AUTOSAR XML (schema 4-2-2)
package /ETAS_BIP
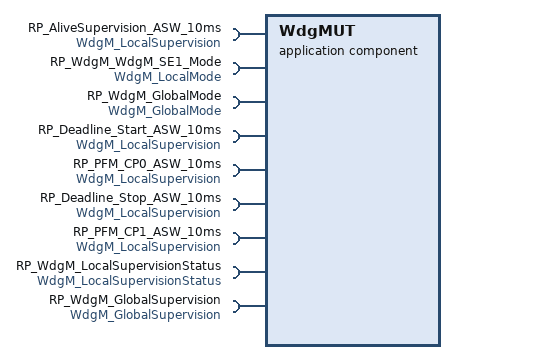
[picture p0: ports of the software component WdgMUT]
  application sw component type WdgMUT
    9 x require port:
      RP_AliveSupervision_ASW_10ms: required-interface=WdgM_LocalSupervision
      RP_WdgM_WdgM_SE1_Mode: required-interface=WdgM_LocalMode
      RP_WdgM_GlobalMode: required-interface=WdgM_GlobalMode
      RP_Deadline_Start_ASW_10ms: required-interface=WdgM_LocalSupervision
      RP_PFM_CP0_ASW_10ms: required-interface=WdgM_LocalSupervision
      RP_Deadline_Stop_ASW_10ms: required-interface=WdgM_LocalSupervision
      RP_PFM_CP1_ASW_10ms: required-interface=WdgM_LocalSupervision
      RP_WdgM_LocalSupervisionStatus: required-interface=WdgM_LocalSupervisionStatus
      RP_WdgM_GlobalSupervision: required-interface=WdgM_GlobalSupervision
    behavior IB_WdgMUT: data-type-mapping=WdgM_Type_Map
      5 x timing event, all with period=0.01:
        TE_ASW_10ms_Alive: start-on-event=RE_WdgMUT_ASW_10ms_Alive
        TE_WdgM_LocalSupervisionStatus: start-on-event=RE_WdgM_LocalSupervisionStatus
        TE_WdgM_GlobalSupervision: start-on-event=RE_WdgM_GlobalSupervision
        TE_ASW_10ms_Deadline: start-on-event=RE_WdgMUT_ASW_10ms_Deadline
        TE_ASW_10ms_Logical: start-on-event=RE_WdgMUT_ASW_10ms_Logical
      5 x runnable:
        RE_WdgMUT_ASW_10ms_Alive: mode-access-points=[RP_WdgM_WdgM_SE1_Mode.currentMode, RP_WdgM_GlobalMode.currentMode]
          sync call SSCP_Alive_CP: operation=RP_AliveSupervision_ASW_10ms.CheckpointReached
        RE_WdgMUT_ASW_10ms_Deadline
          sync call SSCP_Deadline_Start_CP: operation=RP_Deadline_Start_ASW_10ms.CheckpointReached
          sync call SSCP_Deadline_Stop_CP: operation=RP_Deadline_Stop_ASW_10ms.CheckpointReached
        RE_WdgMUT_ASW_10ms_Logical
          sync call SSCP_PFM_CP_0: operation=RP_PFM_CP0_ASW_10ms.CheckpointReached
          sync call SSCP_PFM_CP_1: operation=RP_PFM_CP1_ASW_10ms.CheckpointReached
        RE_WdgM_LocalSupervisionStatus
          sync call SynchronousServerCallPoint_0: operation=RP_WdgM_LocalSupervisionStatus.GetLocalStatus
        RE_WdgM_GlobalSupervision
          5 x sync call:
            SynchronousServerCallPoint_0: operation=RP_WdgM_GlobalSupervision.GetFirstExpiredSEID
            SynchronousServerCallPoint_1: operation=RP_WdgM_GlobalSupervision.GetGlobalStatus
            SynchronousServerCallPoint_2: operation=RP_WdgM_GlobalSupervision.GetMode
            SynchronousServerCallPoint_3: operation=RP_WdgM_GlobalSupervision.PerformReset
            SynchronousServerCallPoint_4: operation=RP_WdgM_GlobalSupervision.SetMode
